# STM32G071 register map
File version: 2.1
CPU: CM0 r0p1, little endian, MPU, no FPU, 4 interrupt priority bits
Registers are 32-bit, read-write, reset 0x0 unless marked. A register's access mark holds for its fields unless they carry their own. Offsets are from the block's base; [hi:lo] are bit positions.

## LPTIM1 — Low power timer
Base 0x40007C00
Same registers: LPTIM2 0x40009400
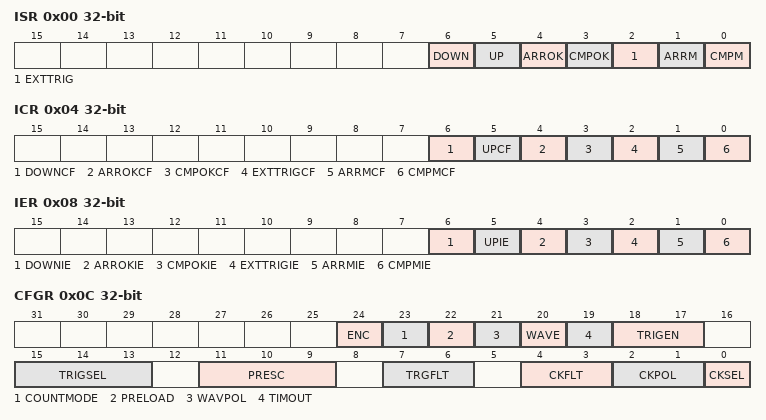
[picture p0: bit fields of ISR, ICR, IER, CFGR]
0x00 ISR ro — Interrupt and Status Register
  [6] DOWN — Counter direction change up to down
  [5] UP — Counter direction change down to up
  [4] ARROK — Autoreload register update OK
  [3] CMPOK — Compare register update OK
  [2] EXTTRIG — External trigger edge event
  [1] ARRM — Autoreload match
  [0] CMPM — Compare match
0x04 ICR wo — Interrupt Clear Register
  [6] DOWNCF — Direction change to down Clear Flag
  [5] UPCF — Direction change to UP Clear Flag
  [4] ARROKCF — Autoreload register update OK Clear Flag
  [3] CMPOKCF — Compare register update OK Clear Flag
  [2] EXTTRIGCF — External trigger valid edge Clear Flag
  [1] ARRMCF — Autoreload match Clear Flag
  [0] CMPMCF — compare match Clear Flag
0x08 IER — Interrupt Enable Register
  [6] DOWNIE — Direction change to down Interrupt Enable
  [5] UPIE — Direction change to UP Interrupt Enable
  [4] ARROKIE — Autoreload register update OK Interrupt Enable
  [3] CMPOKIE — Compare register update OK Interrupt Enable
  [2] EXTTRIGIE — External trigger valid edge Interrupt Enable
  [1] ARRMIE — Autoreload match Interrupt Enable
  [0] CMPMIE — Compare match Interrupt Enable
0x0C CFGR — Configuration Register
  [24] ENC — Encoder mode enable
  [23] COUNTMODE — counter mode enabled
  [22] PRELOAD — Registers update mode
  [21] WAVPOL — Waveform shape polarity
  [20] WAVE — Waveform shape
  [19] TIMOUT — Timeout enable
  [18:17] TRIGEN — Trigger enable and polarity
  [15:13] TRIGSEL — Trigger selector
  [11:9] PRESC — Clock prescaler
  [7:6] TRGFLT — Configurable digital filter for trigger
  [4:3] CKFLT — Configurable digital filter for external clock
  [2:1] CKPOL — Clock Polarity
  [0] CKSEL — Clock selector
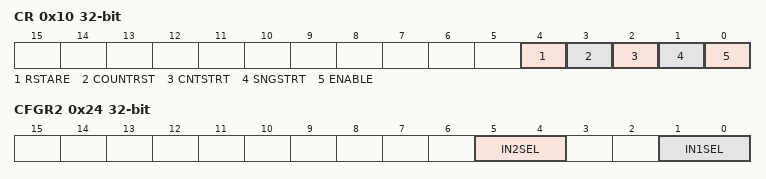
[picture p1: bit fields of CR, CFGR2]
0x10 CR — Control Register
  [4] RSTARE — Reset after read enable
  [3] COUNTRST — Counter reset
  [2] CNTSTRT — Timer start in continuous mode
  [1] SNGSTRT — LPTIM start in single mode
  [0] ENABLE — LPTIM Enable
0x14 CMP — Compare Register
  [15:0] CMP — Compare value
0x18 ARR reset 0x1 — Autoreload Register
  [15:0] ARR — Auto reload value
0x1C CNT ro — Counter Register
  [15:0] CNT — Counter value
0x24 CFGR2 — LPTIM configuration register 2
  [5:4] IN2SEL — LPTIM1 Input 2 selection
  [1:0] IN1SEL — LPTIMx Input 1 selection

## TIM14 — General purpose timers
Base 0x40002000
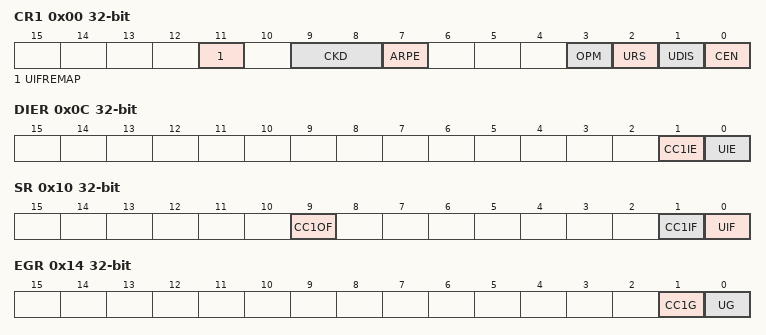
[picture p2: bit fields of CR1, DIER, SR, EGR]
0x00 CR1 — control register 1
  [11] UIFREMAP — UIF status bit remapping
  [9:8] CKD — Clock division
  [7] ARPE — Auto-reload preload enable
  [3] OPM — One-pulse mode
  [2] URS — Update request source
  [1] UDIS — Update disable
  [0] CEN — Counter enable
0x0C DIER — DMA/Interrupt enable register
  [1] CC1IE — Capture/Compare 1 interrupt enable
  [0] UIE — Update interrupt enable
0x10 SR — status register
  [9] CC1OF — Capture/Compare 1 overcapture flag
  [1] CC1IF — Capture/compare 1 interrupt flag
  [0] UIF — Update interrupt flag
0x14 EGR wo — event generation register
  [1] CC1G — Capture/compare 1 generation
  [0] UG — Update generation
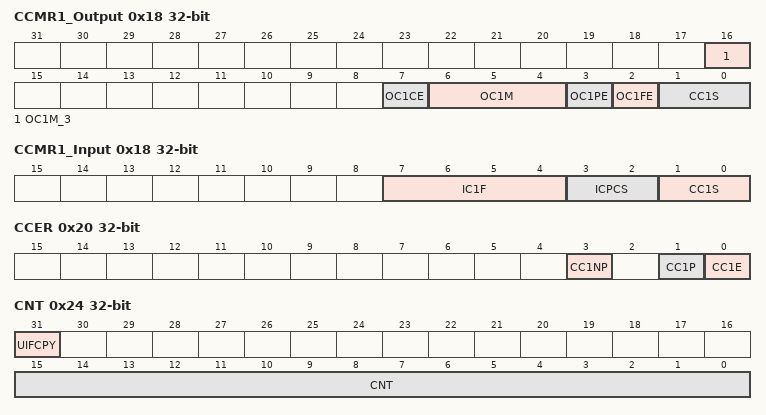
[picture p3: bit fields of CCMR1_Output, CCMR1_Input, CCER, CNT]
0x18 CCMR1_Output — capture/compare mode register 1 (output mode)
  [16] OC1M_3 — Output Compare 1 mode - bit 3
  [7] OC1CE
  [6:4] OC1M
  [3] OC1PE
  [2] OC1FE
  [1:0] CC1S
0x18 CCMR1_Input (alternate view of CCMR1_Output) — capture/compare mode register 1 (input mode)
  [7:4] IC1F — Input capture 1 filter
  [3:2] ICPCS — Input capture 1 prescaler
  [1:0] CC1S — Capture/Compare 1 selection
0x20 CCER — capture/compare enable register
  [3] CC1NP — Capture/Compare 1 output Polarity
  [1] CC1P — Capture/Compare 1 output Polarity
  [0] CC1E — Capture/Compare 1 output enable
0x24 CNT — counter
  [31] UIFCPY — UIF Copy
  [15:0] CNT — low counter value
0x28 PSC — prescaler
  [15:0] PSC — Prescaler value
0x2C ARR — auto-reload register
  [15:0] ARR — Low Auto-reload value
0x34 CCR1 — capture/compare register 1
  [15:0] CCR1 — Low Capture/Compare 1 value
0x68 TISEL — TIM timer input selection register
  [3:0] TISEL — TI1[0] to TI1[15] input selection

## TIM6 — Basic timers
Base 0x40001000
Same registers: TIM7 0x40001400
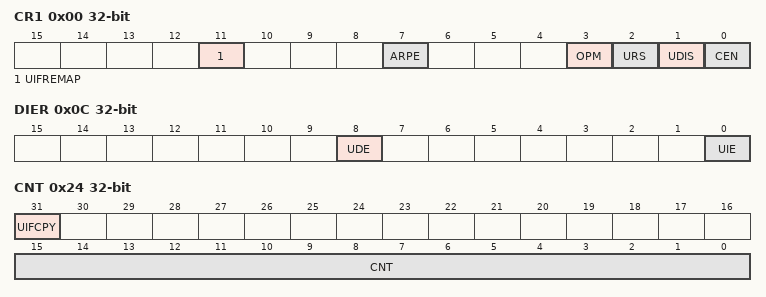
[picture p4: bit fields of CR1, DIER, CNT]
0x00 CR1 — control register 1
  [11] UIFREMAP — UIF status bit remapping
  [7] ARPE — Auto-reload preload enable
  [3] OPM — One-pulse mode
  [2] URS — Update request source
  [1] UDIS — Update disable
  [0] CEN — Counter enable
0x04 CR2 — control register 2
  [6:4] MMS — Master mode selection
0x0C DIER — DMA/Interrupt enable register
  [8] UDE — Update DMA request enable
  [0] UIE — Update interrupt enable
0x10 SR — status register
  [0] UIF — Update interrupt flag
0x14 EGR wo — event generation register
  [0] UG — Update generation
0x24 CNT — counter
  [31] UIFCPY — UIF Copy
  [15:0] CNT — Low counter value
0x28 PSC — prescaler
  [15:0] PSC — Prescaler value
0x2C ARR — auto-reload register
  [15:0] ARR — Low Auto-reload value
